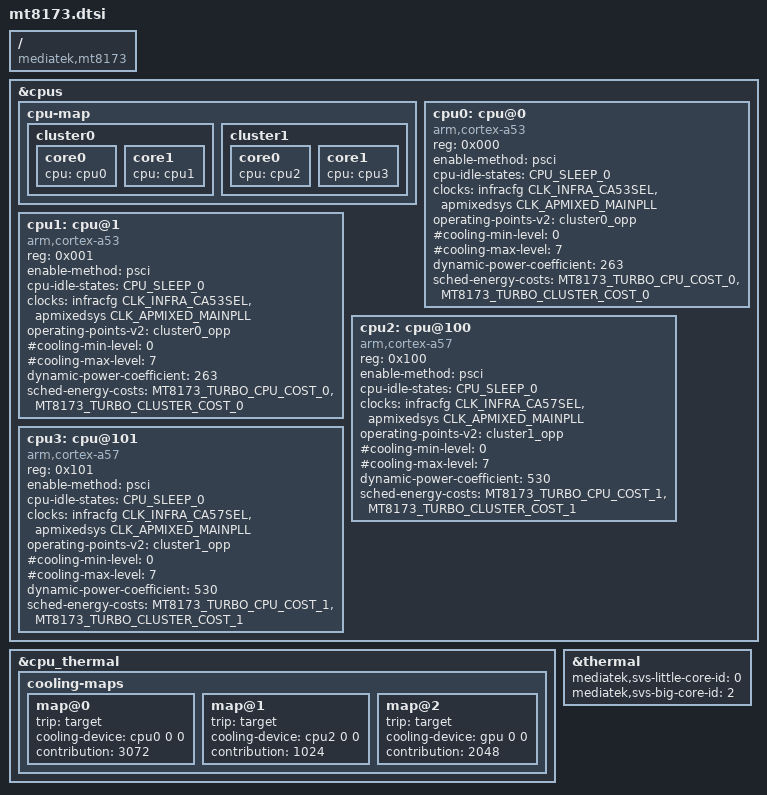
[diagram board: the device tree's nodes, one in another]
/*
 * Copyright (c) 2014 MediaTek Inc.
 * Author: Eddie Huang <eddie.huang@mediatek.com>
 *
 * This program is free software; you can redistribute it and/or modify
 * it under the terms of the GNU General Public License version 2 as
 * published by the Free Software Foundation.
 *
 * This program is distributed in the hope that it will be useful,
 * MERCHANTABILITY or FITNESS FOR A PARTICULAR PURPOSE.  See the
 * GNU General Public License for more details.
 */

#include "mt817x.dtsi"

/ {
	compatible = "mediatek,mt8173";
};

&cpus {
	cpu-map {
		cluster0 {
			core0 {
				cpu = <&cpu0>;
			};
			core1 {
				cpu = <&cpu1>;
			};
		};

		cluster1 {
			core0 {
				cpu = <&cpu2>;
			};
			core1 {
				cpu = <&cpu3>;
			};
		};
	};

	cpu0: cpu@0 {
		device_type = "cpu";
		compatible = "arm,cortex-a53";
		reg = <0x000>;
		enable-method = "psci";
		cpu-idle-states = <&CPU_SLEEP_0>;
		clocks = <&infracfg CLK_INFRA_CA53SEL>,
			 <&apmixedsys CLK_APMIXED_MAINPLL>;
		clock-names = "cpu", "intermediate";
		operating-points-v2 = <&cluster0_opp>;
		#cooling-cells = <2>;
		#cooling-min-level = <0>;
		#cooling-max-level = <7>;
		dynamic-power-coefficient = <263>;
		sched-energy-costs = <&MT8173_TURBO_CPU_COST_0
				      &MT8173_TURBO_CLUSTER_COST_0>;
	};

	cpu1: cpu@1 {
		device_type = "cpu";
		compatible = "arm,cortex-a53";
		reg = <0x001>;
		enable-method = "psci";
		cpu-idle-states = <&CPU_SLEEP_0>;
		clocks = <&infracfg CLK_INFRA_CA53SEL>,
			 <&apmixedsys CLK_APMIXED_MAINPLL>;
		clock-names = "cpu", "intermediate";
		operating-points-v2 = <&cluster0_opp>;
		#cooling-cells = <2>;
		#cooling-min-level = <0>;
		#cooling-max-level = <7>;
		dynamic-power-coefficient = <263>;
		sched-energy-costs = <&MT8173_TURBO_CPU_COST_0
				      &MT8173_TURBO_CLUSTER_COST_0>;
	};

	cpu2: cpu@100 {
		device_type = "cpu";
		compatible = "arm,cortex-a57";
		reg = <0x100>;
		enable-method = "psci";
		cpu-idle-states = <&CPU_SLEEP_0>;
		clocks = <&infracfg CLK_INFRA_CA57SEL>,
			 <&apmixedsys CLK_APMIXED_MAINPLL>;
		clock-names = "cpu", "intermediate";
		operating-points-v2 = <&cluster1_opp>;
		#cooling-cells = <2>;
		#cooling-min-level = <0>;
		#cooling-max-level = <7>;
		dynamic-power-coefficient = <530>;
		sched-energy-costs = <&MT8173_TURBO_CPU_COST_1
				      &MT8173_TURBO_CLUSTER_COST_1>;
	};

	cpu3: cpu@101 {
		device_type = "cpu";
		compatible = "arm,cortex-a57";
		reg = <0x101>;
		enable-method = "psci";
		cpu-idle-states = <&CPU_SLEEP_0>;
		clocks = <&infracfg CLK_INFRA_CA57SEL>,
			 <&apmixedsys CLK_APMIXED_MAINPLL>;
		clock-names = "cpu", "intermediate";
		operating-points-v2 = <&cluster1_opp>;
		#cooling-cells = <2>;
		#cooling-min-level = <0>;
		#cooling-max-level = <7>;
		dynamic-power-coefficient = <530>;
		sched-energy-costs = <&MT8173_TURBO_CPU_COST_1
				      &MT8173_TURBO_CLUSTER_COST_1>;
	};

	/include/ "mt817x-sched-energy.dtsi"
};

&cpu_thermal {
	cooling-maps {
		map@0 {
			trip = <&target>;
			cooling-device = <&cpu0 0 0>;
			contribution = <3072>;
		};
		map@1 {
			trip = <&target>;
			cooling-device = <&cpu2 0 0>;
			contribution = <1024>;
		};
		map@2 {
			trip = <&target>;
			cooling-device = <&gpu 0 0>;
			contribution = <2048>;
		};
	};
};

&thermal {
	mediatek,svs-little-core-id = <0>;
	mediatek,svs-big-core-id = <2>;
};
